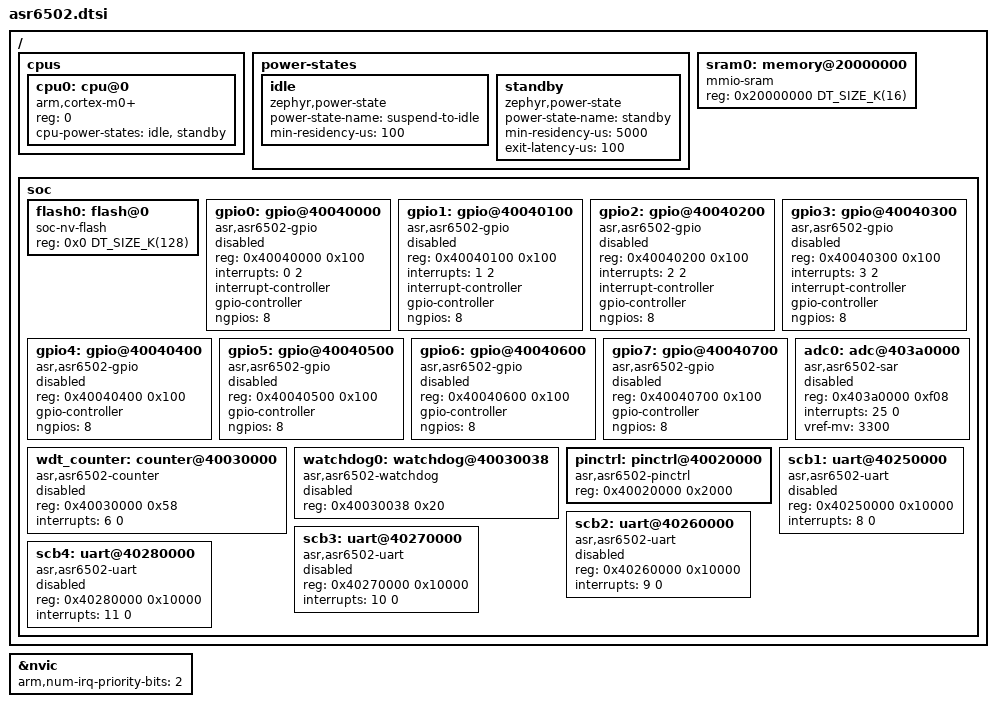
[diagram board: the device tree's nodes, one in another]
/*
 * Copyright (c) 2025 hal_ASR6502 contributors
 *
 * SPDX-License-Identifier: Apache-2.0
 */

#include <arm/armv6-m.dtsi>
#include <mem.h>
#include <zephyr/dt-bindings/gpio/gpio.h>

/ {
	cpus {
		#address-cells = <1>;
		#size-cells = <0>;

		cpu0: cpu@0 {
			device_type = "cpu";
			compatible = "arm,cortex-m0+";
			reg = <0>;
			cpu-power-states = <&idle &standby>;
		};
	};

	power-states {
		idle: idle {
			compatible = "zephyr,power-state";
			power-state-name = "suspend-to-idle";
			min-residency-us = <100>;
		};

		standby: standby {
			compatible = "zephyr,power-state";
			power-state-name = "standby";
			min-residency-us = <5000>;
			exit-latency-us = <100>;
		};
	};

	sram0: memory@20000000 {
		compatible = "mmio-sram";
		reg = <0x20000000 DT_SIZE_K(16)>;
	};

	soc {
		flash0: flash@0 {
			compatible = "soc-nv-flash";
			reg = <0x0 DT_SIZE_K(128)>;
		};

		gpio0: gpio@40040000 {
			compatible = "asr,asr6502-gpio";
			reg = <0x40040000 0x100>;
			interrupts = <0 2>;
			interrupt-controller;
			#interrupt-cells = <2>;
			gpio-controller;
			#gpio-cells = <2>;
			ngpios = <8>;
			status = "disabled";
		};

		gpio1: gpio@40040100 {
			compatible = "asr,asr6502-gpio";
			reg = <0x40040100 0x100>;
			interrupts = <1 2>;
			interrupt-controller;
			#interrupt-cells = <2>;
			gpio-controller;
			#gpio-cells = <2>;
			ngpios = <8>;
			status = "disabled";
		};

		gpio2: gpio@40040200 {
			compatible = "asr,asr6502-gpio";
			reg = <0x40040200 0x100>;
			interrupts = <2 2>;
			interrupt-controller;
			#interrupt-cells = <2>;
			gpio-controller;
			#gpio-cells = <2>;
			ngpios = <8>;
			status = "disabled";
		};

		gpio3: gpio@40040300 {
			compatible = "asr,asr6502-gpio";
			reg = <0x40040300 0x100>;
			interrupts = <3 2>;
			interrupt-controller;
			#interrupt-cells = <2>;
			gpio-controller;
			#gpio-cells = <2>;
			ngpios = <8>;
			status = "disabled";
		};

		gpio4: gpio@40040400 {
			compatible = "asr,asr6502-gpio";
			reg = <0x40040400 0x100>;
			gpio-controller;
			#gpio-cells = <2>;
			ngpios = <8>;
			status = "disabled";
		};

		gpio5: gpio@40040500 {
			compatible = "asr,asr6502-gpio";
			reg = <0x40040500 0x100>;
			gpio-controller;
			#gpio-cells = <2>;
			ngpios = <8>;
			status = "disabled";
		};

		gpio6: gpio@40040600 {
			compatible = "asr,asr6502-gpio";
			reg = <0x40040600 0x100>;
			gpio-controller;
			#gpio-cells = <2>;
			ngpios = <8>;
			status = "disabled";
		};

		gpio7: gpio@40040700 {
			compatible = "asr,asr6502-gpio";
			reg = <0x40040700 0x100>;
			gpio-controller;
			#gpio-cells = <2>;
			ngpios = <8>;
			status = "disabled";
		};
		adc0: adc@403a0000 {
			compatible = "asr,asr6502-sar";
			reg = <0x403a0000 0xf08>;
			interrupts = <25 0>;
			#io-channel-cells = <1>;
			vref-mv = <3300>;
			status = "disabled";
		};

		wdt_counter: counter@40030000 {
			compatible = "asr,asr6502-counter";
			reg = <0x40030000 0x58>;
			interrupts = <6 0>;
			status = "disabled";
		};

		/* Alternative role for the same WDT hardware; enable either this
		 * or wdt_counter, never both.
		 */
		watchdog0: watchdog@40030038 {
			compatible = "asr,asr6502-watchdog";
			reg = <0x40030038 0x20>;
			status = "disabled";
		};

		pinctrl: pinctrl@40020000 {
			compatible = "asr,asr6502-pinctrl";
			reg = <0x40020000 0x2000>;
		};

		scb1: uart@40250000 {
			compatible = "asr,asr6502-uart";
			reg = <0x40250000 0x10000>;
			interrupts = <8 0>;
			status = "disabled";
		};

		scb2: uart@40260000 {
			compatible = "asr,asr6502-uart";
			reg = <0x40260000 0x10000>;
			interrupts = <9 0>;
			status = "disabled";
		};

		scb3: uart@40270000 {
			compatible = "asr,asr6502-uart";
			reg = <0x40270000 0x10000>;
			interrupts = <10 0>;
			status = "disabled";
		};

		scb4: uart@40280000 {
			compatible = "asr,asr6502-uart";
			reg = <0x40280000 0x10000>;
			interrupts = <11 0>;
			status = "disabled";
		};
	};
};

&nvic {
	arm,num-irq-priority-bits = <2>;
};
